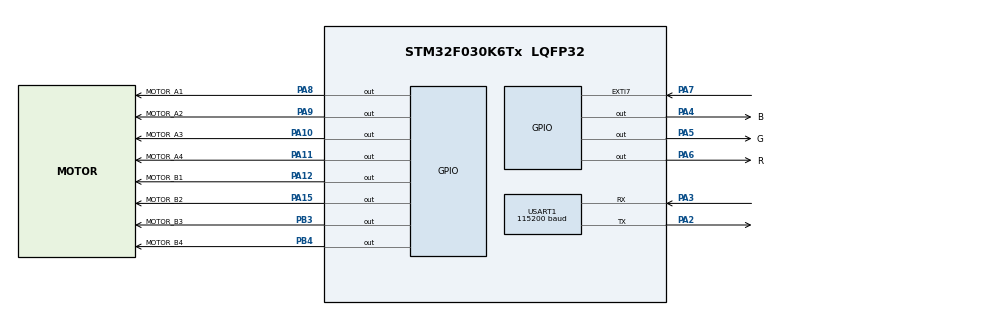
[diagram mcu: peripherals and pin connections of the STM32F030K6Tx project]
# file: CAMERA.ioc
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IWDG.Prescaler=IWDG_PRESCALER_64
Mcu.Family=STM32F0
Mcu.Name=STM32F030K6Tx
Mcu.Package=LQFP32
NVIC.USART1_IRQn=true\:0\:0\:false\:false\:true\:true\:true
PA10.GPIO_Label=MOTOR_A3
PA10.PinState=GPIO_PIN_SET
PA10.Signal=GPIO_Output
PA11.GPIO_Label=MOTOR_A4
PA11.GPIO_Speed=GPIO_SPEED_FREQ_HIGH
PA11.PinState=GPIO_PIN_SET
PA11.Signal=GPIO_Output
PA12.GPIO_Label=MOTOR_B1
PA12.GPIO_Speed=GPIO_SPEED_FREQ_HIGH
PA12.PinState=GPIO_PIN_SET
PA12.Signal=GPIO_Output
PA13.Mode=Serial_Wire
PA13.Signal=SYS_SWDIO
PA14.Mode=Serial_Wire
PA14.Signal=SYS_SWCLK
PA15.GPIO_Label=MOTOR_B2
PA15.GPIO_Speed=GPIO_SPEED_FREQ_HIGH
PA15.PinState=GPIO_PIN_SET
PA15.Signal=GPIO_Output
PA2.Mode=Asynchronous
PA2.Signal=USART1_TX
PA3.Mode=Asynchronous
PA3.Signal=USART1_RX
PA4.GPIO_Label=B
PA4.Signal=GPIO_Output
PA5.GPIO_Label=G
PA5.Signal=GPIO_Output
PA6.GPIO_Label=R
PA6.Signal=GPIO_Output
PA7.Signal=GPXTI7
PA8.GPIO_Label=MOTOR_A1
PA8.PinState=GPIO_PIN_SET
PA8.Signal=GPIO_Output
PA9.GPIO_Label=MOTOR_A2
PA9.PinState=GPIO_PIN_SET
PA9.Signal=GPIO_Output
PB3.GPIO_Label=MOTOR_B3
PB3.PinState=GPIO_PIN_SET
PB3.Signal=GPIO_Output
PB4.GPIO_Label=MOTOR_B4
PB4.PinState=GPIO_PIN_SET
PB4.Signal=GPIO_Output
ProjectManager.HeapSize=0x200
ProjectManager.StackSize=0x400
ProjectManager.TargetToolchain=EWARM V7
USART1.BaudRate=115200
USART1.VirtualMode-Asynchronous=VM_ASYNC
VP_IWDG_VS_IWDG.Mode=IWDG_Activate
board=custom

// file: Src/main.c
/* USER CODE BEGIN Header */
/**
******************************************************************************
* @file           : main.c
* @brief          : Main program body
******************************************************************************
* @attention
*
* <h2><center>&copy; Copyright (c) 2020 STMicroelectronics.
* All rights reserved.</center></h2>
*
* This software component is licensed by ST under BSD 3-Clause license,
* the "License"; You may not use this file except in compliance with the
* License. You may obtain a copy of the License at:
*                        opensource.org/licenses/BSD-3-Clause
*
******************************************************************************
*/
/* USER CODE END Header */

#include "main.h"

/* USER CODE BEGIN Includes */
#include "step_motor.h"
#include "sensor.h"
/* USER CODE END Includes */

IWDG_HandleTypeDef hiwdg;

UART_HandleTypeDef huart1;

void SystemClock_Config(void);
static void MX_GPIO_Init(void);
static void MX_USART1_UART_Init(void);
static void MX_IWDG_Init(void);

/* USER CODE BEGIN 0 */
unsigned char rxtemp;
/* USER CODE END 0 */

int main(void)
{

  /* MCU Configuration--------------------------------------------------------*/

  /* Reset of all peripherals, Initializes the Flash interface and the Systick. */
  HAL_Init();

  /* Configure the system clock */
  SystemClock_Config();

  /* Initialize all configured peripherals */
  MX_GPIO_Init();
  MX_USART1_UART_Init();
  // MX_IWDG_Init();vimvim

  /* USER CODE BEGIN 2 */
  //__HAL_UART_CLEAR_FLAG(&huart1,UART_IT_RXNE);
  //__HAL_UART_ENABLE_IT(&huart1, UART_IT_RXNE);	//使能空闲中断
  //HAL_UART_Receive_IT(&huart1,&rxtemp,1);
  //HAL_UART_Receive_IT(&huart1,&rxtemp,1);;
  //rgb_control(RGB_BLUE_ON);

  /* USER CODE END 2 */

  /* Infinite loop */
  while (1)
  {

    /* USER CODE BEGIN 3 */
#define ANGLE		360

	//HAL_IWDG_Refresh(&hiwdg);
	//uint8_t pData[]={0x10,0x02,0x70,0x00,0x00,0x10,0x03};
	// uart_analysis();
	// HAL_UART_Transmit(&huart1, pData, 7,100);
	//uart_test();
	//    		rgb_control(RGB_RED_ON);
	//    step_motor(ANGLE,YAW,FORWARD);
	//    		rgb_control(RGB_GREEN_ON);
	//    HAL_Delay(3000);
	//    step_motor(ANGLE,YAW,BACKWARD);
	//    		rgb_control(RGB_BLUE_ON);
	//    		HAL_Delay(1000);
	//    		step_motor(ANGLE,PITCH,FORWARD);
	//		//rgb_control(RGB_ALL_OFF);
	//		HAL_Delay(1000);
	//		step_motor(ANGLE,PITCH,BACKWARD);
	//		HAL_Delay(1000);
  }
  /* USER CODE END 3 */
}

void SystemClock_Config(void)
{
  RCC_OscInitTypeDef RCC_OscInitStruct = {0};
  RCC_ClkInitTypeDef RCC_ClkInitStruct = {0};
  RCC_PeriphCLKInitTypeDef PeriphClkInit = {0};

  /** Initializes the CPU, AHB and APB busses clocks
  */
  RCC_OscInitStruct.OscillatorType = RCC_OSCILLATORTYPE_HSI|RCC_OSCILLATORTYPE_LSI;
  RCC_OscInitStruct.HSIState = RCC_HSI_ON;
  RCC_OscInitStruct.HSICalibrationValue = RCC_HSICALIBRATION_DEFAULT;
  RCC_OscInitStruct.LSIState = RCC_LSI_ON;
  RCC_OscInitStruct.PLL.PLLState = RCC_PLL_NONE;
  if (HAL_RCC_OscConfig(&RCC_OscInitStruct) != HAL_OK)
  {
    Error_Handler();
  }
  /** Initializes the CPU, AHB and APB busses clocks
  */
  RCC_ClkInitStruct.ClockType = RCC_CLOCKTYPE_HCLK|RCC_CLOCKTYPE_SYSCLK
    |RCC_CLOCKTYPE_PCLK1;
  RCC_ClkInitStruct.SYSCLKSource = RCC_SYSCLKSOURCE_HSI;
  RCC_ClkInitStruct.AHBCLKDivider = RCC_SYSCLK_DIV1;
  RCC_ClkInitStruct.APB1CLKDivider = RCC_HCLK_DIV1;

  if (HAL_RCC_ClockConfig(&RCC_ClkInitStruct, FLASH_LATENCY_0) != HAL_OK)
  {
    Error_Handler();
  }
  PeriphClkInit.PeriphClockSelection = RCC_PERIPHCLK_USART1;
  PeriphClkInit.Usart1ClockSelection = RCC_USART1CLKSOURCE_PCLK1;
  if (HAL_RCCEx_PeriphCLKConfig(&PeriphClkInit) != HAL_OK)
  {
    Error_Handler();
  }
}

static void MX_IWDG_Init(void)
{

  hiwdg.Instance = IWDG;
  hiwdg.Init.Prescaler = IWDG_PRESCALER_64;
  hiwdg.Init.Window = 4095;
  hiwdg.Init.Reload = 4095;
  if (HAL_IWDG_Init(&hiwdg) != HAL_OK)
  {
    Error_Handler();
  }

}

static void MX_USART1_UART_Init(void)
{

  huart1.Instance = USART1;
  huart1.Init.BaudRate = 115200;
  huart1.Init.WordLength = UART_WORDLENGTH_8B;
  huart1.Init.StopBits = UART_STOPBITS_1;
  huart1.Init.Parity = UART_PARITY_NONE;
  huart1.Init.Mode = UART_MODE_TX_RX;
  huart1.Init.HwFlowCtl = UART_HWCONTROL_NONE;
  huart1.Init.OverSampling = UART_OVERSAMPLING_16;
  huart1.Init.OneBitSampling = UART_ONE_BIT_SAMPLE_DISABLE;
  huart1.AdvancedInit.AdvFeatureInit = UART_ADVFEATURE_NO_INIT;
  if (HAL_UART_Init(&huart1) != HAL_OK)
  {
    Error_Handler();
  }

}

static void MX_GPIO_Init(void)
{
  GPIO_InitTypeDef GPIO_InitStruct = {0};

  /* GPIO Ports Clock Enable */
  __HAL_RCC_GPIOA_CLK_ENABLE();
  __HAL_RCC_GPIOB_CLK_ENABLE();

  /*Configure GPIO pin Output Level */
  HAL_GPIO_WritePin(GPIOA, B_Pin|G_Pin|R_Pin, GPIO_PIN_RESET);

  /*Configure GPIO pin Output Level */
  HAL_GPIO_WritePin(GPIOA, MOTOR_A1_Pin|MOTOR_A2_Pin|MOTOR_A3_Pin|MOTOR_A4_Pin
                    |MOTOR_B1_Pin|MOTOR_B2_Pin, GPIO_PIN_SET);

  /*Configure GPIO pin Output Level */
  HAL_GPIO_WritePin(GPIOB, MOTOR_B3_Pin|MOTOR_B4_Pin, GPIO_PIN_SET);

  /*Configure GPIO pins : B_Pin G_Pin R_Pin MOTOR_A1_Pin
  MOTOR_A2_Pin MOTOR_A3_Pin */
  GPIO_InitStruct.Pin = B_Pin|G_Pin|R_Pin|MOTOR_A1_Pin
    |MOTOR_A2_Pin|MOTOR_A3_Pin;
  GPIO_InitStruct.Mode = GPIO_MODE_OUTPUT_PP;
  GPIO_InitStruct.Pull = GPIO_NOPULL;
  GPIO_InitStruct.Speed = GPIO_SPEED_FREQ_LOW;
  HAL_GPIO_Init(GPIOA, &GPIO_InitStruct);

  /*Configure GPIO pin : PA7 */
  GPIO_InitStruct.Pin = GPIO_PIN_7;
  GPIO_InitStruct.Mode = GPIO_MODE_IT_RISING;
  GPIO_InitStruct.Pull = GPIO_NOPULL;
  HAL_GPIO_Init(GPIOA, &GPIO_InitStruct);

  /*Configure GPIO pins : MOTOR_A4_Pin MOTOR_B1_Pin MOTOR_B2_Pin */
  GPIO_InitStruct.Pin = MOTOR_A4_Pin|MOTOR_B1_Pin|MOTOR_B2_Pin;
  GPIO_InitStruct.Mode = GPIO_MODE_OUTPUT_PP;
  GPIO_InitStruct.Pull = GPIO_NOPULL;
  GPIO_InitStruct.Speed = GPIO_SPEED_FREQ_HIGH;
  HAL_GPIO_Init(GPIOA, &GPIO_InitStruct);

  /*Configure GPIO pins : MOTOR_B3_Pin MOTOR_B4_Pin */
  GPIO_InitStruct.Pin = MOTOR_B3_Pin|MOTOR_B4_Pin;
  GPIO_InitStruct.Mode = GPIO_MODE_OUTPUT_PP;
  GPIO_InitStruct.Pull = GPIO_NOPULL;
  GPIO_InitStruct.Speed = GPIO_SPEED_FREQ_LOW;
  HAL_GPIO_Init(GPIOB, &GPIO_InitStruct);
  HAL_GPIO_WritePin(GPIOA, MOTOR_A1_Pin|MOTOR_A2_Pin|MOTOR_A3_Pin|MOTOR_A4_Pin, GPIO_PIN_RESET);
  HAL_GPIO_WritePin(GPIOA, MOTOR_B1_Pin|MOTOR_B2_Pin, GPIO_PIN_RESET);
  HAL_GPIO_WritePin(GPIOB, MOTOR_B3_Pin|MOTOR_B4_Pin, GPIO_PIN_RESET);
}

void Error_Handler(void)
{
}

/************************ (C) COPYRIGHT STMicroelectronics *****END OF FILE****/
